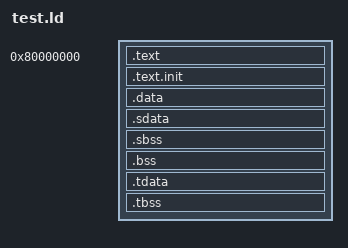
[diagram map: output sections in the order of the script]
/*======================================================================*/
/* Proxy kernel linker script                                           */
/*======================================================================*/
/* This is the linker script used when building the proxy kernel. */

/*----------------------------------------------------------------------*/
/* Setup                                                                */
/*----------------------------------------------------------------------*/

/* The OUTPUT_ARCH command specifies the machine architecture where the
   argument is one of the names used in the BFD library. More
   specifically one of the entires in bfd/cpu-mips.c */

OUTPUT_ARCH( "riscv" )

/*----------------------------------------------------------------------*/
/* Sections                                                             */
/*----------------------------------------------------------------------*/
ENTRY(main)
SECTIONS
{

  . = 0x80000000;
    .text           :
    {
      *(.text)
      *(.text.unlikely .text.*_unlikely .text.unlikely.*)
      *(.text.exit .text.exit.*)
      *(.text.startup .text.startup.*)
      *(.text.hot .text.hot.*)
      *(.stub .text.* .gnu.linkonce.t.*)
      /* .gnu.warning sections are handled specially by elf32.em.  */
      *(.gnu.warning)
    }

  .text.init : { crt.o(.text) }


  /* data segment */
  .data : { *(.data) }

  .sdata : {
    _gp = . + 0x800;
    *(.srodata.cst16) *(.srodata.cst8) *(.srodata.cst4) *(.srodata.cst2) *(.srodata*)
    *(.sdata .sdata.* .gnu.linkonce.s.*)
  }

  /* bss segment */
  .sbss : {
    *(.sbss .sbss.* .gnu.linkonce.sb.*)
    *(.scommon)
  }
  .bss : { *(.bss) }

  /* thread-local data segment */
  .tdata :
  {
    _tls_data = .;
    crt.o(.tdata.begin)
    *(.tdata)
    crt.o(.tdata.end)
  }
  .tbss :
  {
    *(.tbss)
    crt.o(.tbss.end)
  }

  /* End of uninitalized data segement */
  _end = .;
}

